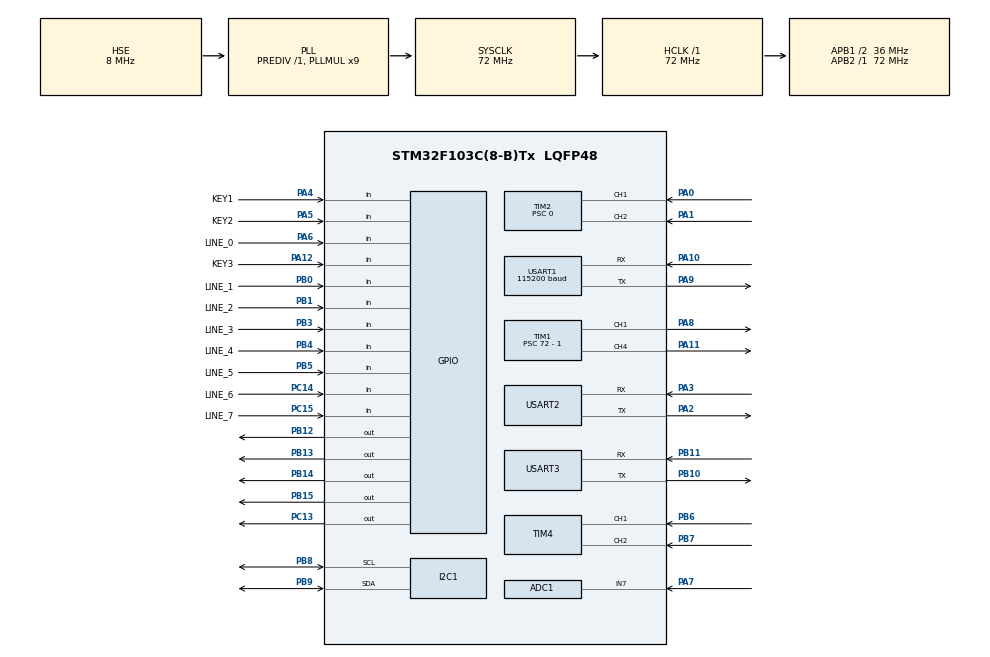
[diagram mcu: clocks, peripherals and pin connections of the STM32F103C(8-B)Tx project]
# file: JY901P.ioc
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ADC1.Channel-2\#ChannelRegularConversion=ADC_CHANNEL_7
ADC1.NbrOfConversionFlag=1
ADC1.Rank-2\#ChannelRegularConversion=1
ADC1.SamplingTime-2\#ChannelRegularConversion=ADC_SAMPLETIME_1CYCLE_5
ADC1.master=1
Dma.Request0=USART1_TX
Dma.Request1=USART1_RX
Dma.USART1_RX.1.Direction=DMA_PERIPH_TO_MEMORY
Dma.USART1_RX.1.Instance=DMA1_Channel5
Dma.USART1_RX.1.MemDataAlignment=DMA_MDATAALIGN_BYTE
Dma.USART1_RX.1.MemInc=DMA_MINC_ENABLE
Dma.USART1_RX.1.Mode=DMA_CIRCULAR
Dma.USART1_RX.1.PeriphDataAlignment=DMA_PDATAALIGN_BYTE
Dma.USART1_RX.1.PeriphInc=DMA_PINC_DISABLE
Dma.USART1_RX.1.Priority=DMA_PRIORITY_LOW
Dma.USART1_TX.0.Direction=DMA_MEMORY_TO_PERIPH
Dma.USART1_TX.0.Instance=DMA1_Channel4
Dma.USART1_TX.0.MemDataAlignment=DMA_MDATAALIGN_BYTE
Dma.USART1_TX.0.MemInc=DMA_MINC_ENABLE
Dma.USART1_TX.0.Mode=DMA_NORMAL
Dma.USART1_TX.0.PeriphDataAlignment=DMA_PDATAALIGN_BYTE
Dma.USART1_TX.0.PeriphInc=DMA_PINC_DISABLE
Dma.USART1_TX.0.Priority=DMA_PRIORITY_LOW
I2C1.I2C_Mode=I2C_Fast
Mcu.Family=STM32F1
Mcu.Name=STM32F103C(8-B)Tx
Mcu.Package=LQFP48
NVIC.DMA1_Channel4_IRQn=true\:0\:0\:false\:false\:true\:false\:true\:true
NVIC.DMA1_Channel5_IRQn=true\:0\:0\:false\:false\:true\:false\:true\:true
NVIC.PriorityGroup=NVIC_PRIORITYGROUP_4
NVIC.TIM2_IRQn=true\:0\:0\:false\:false\:true\:true\:true\:true
NVIC.TIM3_IRQn=true\:0\:0\:false\:false\:true\:true\:true\:true
NVIC.USART1_IRQn=true\:0\:0\:false\:false\:true\:true\:true\:true
NVIC.USART2_IRQn=true\:0\:0\:false\:false\:true\:true\:true\:true
NVIC.USART3_IRQn=true\:0\:0\:false\:false\:true\:true\:true\:true
PA0-WKUP.Signal=S_TIM2_CH1_ETR
PA1.Signal=S_TIM2_CH2
PA10.Mode=Asynchronous
PA10.Signal=USART1_RX
PA11.Signal=S_TIM1_CH4
PA12.GPIO_Label=KEY3
PA12.Signal=GPIO_Input
PA13.Mode=Serial_Wire
PA13.Signal=SYS_JTMS-SWDIO
PA14.Mode=Serial_Wire
PA14.Signal=SYS_JTCK-SWCLK
PA2.Mode=Asynchronous
PA2.Signal=USART2_TX
PA3.Mode=Asynchronous
PA3.Signal=USART2_RX
PA4.GPIO_Label=KEY1
PA4.Signal=GPIO_Input
PA5.GPIO_Label=KEY2
PA5.Signal=GPIO_Input
PA6.GPIO_Label=LINE_0
PA6.GPIO_PuPd=GPIO_PULLUP
PA6.Signal=GPIO_Input
PA7.Signal=ADCx_IN7
PA8.Signal=S_TIM1_CH1
PA9.Mode=Asynchronous
PA9.Signal=USART1_TX
PB0.GPIO_Label=LINE_1
PB0.GPIO_PuPd=GPIO_PULLUP
PB0.Signal=GPIO_Input
PB1.GPIO_Label=LINE_2
PB1.GPIO_PuPd=GPIO_PULLUP
PB1.Signal=GPIO_Input
PB10.Mode=Asynchronous
PB10.Signal=USART3_TX
PB11.Mode=Asynchronous
PB11.Signal=USART3_RX
PB12.Signal=GPIO_Output
PB13.Signal=GPIO_Output
PB14.Signal=GPIO_Output
PB15.Signal=GPIO_Output
PB3.GPIO_Label=LINE_3
PB3.GPIO_PuPd=GPIO_PULLUP
PB3.Signal=GPIO_Input
PB4.GPIO_Label=LINE_4
PB4.GPIO_PuPd=GPIO_PULLUP
PB4.Signal=GPIO_Input
PB5.GPIO_Label=LINE_5
PB5.GPIO_PuPd=GPIO_PULLUP
PB5.Signal=GPIO_Input
PB6.Signal=S_TIM4_CH1
PB7.Signal=S_TIM4_CH2
PB8.Mode=I2C
PB8.Signal=I2C1_SCL
PB9.Mode=I2C
PB9.Signal=I2C1_SDA
PC13-TAMPER-RTC.Signal=GPIO_Output
PC14-OSC32_IN.GPIO_Label=LINE_6
PC14-OSC32_IN.GPIO_PuPd=GPIO_PULLUP
PC14-OSC32_IN.Signal=GPIO_Input
PC15-OSC32_OUT.GPIO_Label=LINE_7
PC15-OSC32_OUT.GPIO_PuPd=GPIO_PULLUP
PC15-OSC32_OUT.Signal=GPIO_Input
PD0-OSC_IN.Mode=HSE-External-Oscillator
PD0-OSC_IN.Signal=RCC_OSC_IN
PD1-OSC_OUT.Mode=HSE-External-Oscillator
PD1-OSC_OUT.Signal=RCC_OSC_OUT
ProjectManager.HeapSize=0x200
ProjectManager.StackSize=0x400
ProjectManager.TargetToolchain=CMake
RCC.ADCPresc=RCC_ADCPCLK2_DIV6
RCC.AHBFreq_Value=72000000
RCC.APB1CLKDivider=RCC_HCLK_DIV2
RCC.APB1Freq_Value=36000000
RCC.APB1TimFreq_Value=72000000
RCC.APB2Freq_Value=72000000
RCC.APB2TimFreq_Value=72000000
RCC.HCLKFreq_Value=72000000
RCC.PLLMUL=RCC_PLL_MUL9
RCC.PLLSourceVirtual=RCC_PLLSOURCE_HSE
RCC.SYSCLKFreq_VALUE=72000000
RCC.SYSCLKSource=RCC_SYSCLKSOURCE_PLLCLK
RCC.USBFreq_Value=72000000
SH.ADCx_IN7.0=ADC1_IN7,IN7
SH.S_TIM1_CH1.0=TIM1_CH1,PWM Generation1 CH1
SH.S_TIM1_CH4.0=TIM1_CH4,PWM Generation4 CH4
SH.S_TIM2_CH1_ETR.0=TIM2_CH1,Encoder_Interface
SH.S_TIM2_CH2.0=TIM2_CH2,Encoder_Interface
SH.S_TIM4_CH1.0=TIM4_CH1,Encoder_Interface
SH.S_TIM4_CH2.0=TIM4_CH2,Encoder_Interface
TIM1.Channel-PWM\ Generation1\ CH1=TIM_CHANNEL_1
TIM1.Channel-PWM\ Generation4\ CH4=TIM_CHANNEL_4
TIM1.Period=999
TIM1.Prescaler=72 - 1
TIM2.EncoderMode=TIM_ENCODERMODE_TI12
TIM2.Period=65535
TIM2.Prescaler=0
TIM3.Period=1000 - 1
TIM3.Prescaler=72 -1 
TIM4.EncoderMode=TIM_ENCODERMODE_TI12
USART1.BaudRate=115200
USART1.VirtualMode=VM_ASYNC
USART2.VirtualMode=VM_ASYNC
USART3.VirtualMode=VM_ASYNC
VP_TIM1_VS_ClockSourceINT.Mode=Internal
VP_TIM3_VS_ClockSourceINT.Mode=Internal
board=custom

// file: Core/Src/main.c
/* USER CODE BEGIN Header */
/**
  ******************************************************************************
  * @file           : main.c
  * @brief          : Main program body
  ******************************************************************************
  * @attention
  *
  * Copyright (c) 2026 STMicroelectronics.
  * All rights reserved.
  *
  * This software is licensed under terms that can be found in the LICENSE file
  * in the root directory of this software component.
  * If no LICENSE file comes with this software, it is provided AS-IS.
  *
  ******************************************************************************
  */
/* USER CODE END Header */
#include "main.h"
#include "adc.h"
#include "dma.h"
#include "i2c.h"
#include "tim.h"
#include "usart.h"
#include "gpio.h"

/* USER CODE BEGIN Includes */
#include "task.h"
#include "uartdbg.h"
#include "motor_bujin.h"
/* USER CODE END Includes */

void SystemClock_Config(void);

int main(void)
{

  /* MCU Configuration--------------------------------------------------------*/

  /* Reset of all peripherals, Initializes the Flash interface and the Systick. */
  HAL_Init();

  /* Configure the system clock */
  SystemClock_Config();

  /* Initialize all configured peripherals */
  MX_GPIO_Init();
  MX_DMA_Init();
  MX_USART1_UART_Init();
  MX_TIM1_Init();
  MX_I2C1_Init();
  MX_TIM2_Init();
  MX_TIM3_Init();
  MX_TIM4_Init();
  MX_ADC1_Init();
  MX_USART2_UART_Init();
  MX_USART3_UART_Init();
  /* USER CODE BEGIN 2 */

  /* 任务调度：1ms 节拍 + DMA 发送 + 电机 FSM */
  task_init();
  // Motor_Step_EmergencyStop();  /* 上电后立即失能电机，避免意外碰撞 */
      /* ── 步进电机测试 ── */
      //  Motor_Step_MoveRel(REV2P(1), 1000);     // 转1圈
      // Motor_Step_MoveRel(DEG2P(90), 30); // 转90°

      /* USER CODE END 2 */

      /* Infinite loop */
      while (1) {

    /* USER CODE BEGIN 3 */
    task_poll();
  }
  /* USER CODE END 3 */
}

void SystemClock_Config(void)
{
  RCC_OscInitTypeDef RCC_OscInitStruct = {0};
  RCC_ClkInitTypeDef RCC_ClkInitStruct = {0};
  RCC_PeriphCLKInitTypeDef PeriphClkInit = {0};

  /** Initializes the RCC Oscillators according to the specified parameters
  * in the RCC_OscInitTypeDef structure.
  */
  RCC_OscInitStruct.OscillatorType = RCC_OSCILLATORTYPE_HSE;
  RCC_OscInitStruct.HSEState = RCC_HSE_ON;
  RCC_OscInitStruct.HSEPredivValue = RCC_HSE_PREDIV_DIV1;
  RCC_OscInitStruct.HSIState = RCC_HSI_ON;
  RCC_OscInitStruct.PLL.PLLState = RCC_PLL_ON;
  RCC_OscInitStruct.PLL.PLLSource = RCC_PLLSOURCE_HSE;
  RCC_OscInitStruct.PLL.PLLMUL = RCC_PLL_MUL9;
  if (HAL_RCC_OscConfig(&RCC_OscInitStruct) != HAL_OK)
  {
    Error_Handler();
  }

  /** Initializes the CPU, AHB and APB buses clocks
  */
  RCC_ClkInitStruct.ClockType = RCC_CLOCKTYPE_HCLK|RCC_CLOCKTYPE_SYSCLK
                              |RCC_CLOCKTYPE_PCLK1|RCC_CLOCKTYPE_PCLK2;
  RCC_ClkInitStruct.SYSCLKSource = RCC_SYSCLKSOURCE_PLLCLK;
  RCC_ClkInitStruct.AHBCLKDivider = RCC_SYSCLK_DIV1;
  RCC_ClkInitStruct.APB1CLKDivider = RCC_HCLK_DIV2;
  RCC_ClkInitStruct.APB2CLKDivider = RCC_HCLK_DIV1;

  if (HAL_RCC_ClockConfig(&RCC_ClkInitStruct, FLASH_LATENCY_2) != HAL_OK)
  {
    Error_Handler();
  }
  PeriphClkInit.PeriphClockSelection = RCC_PERIPHCLK_ADC;
  PeriphClkInit.AdcClockSelection = RCC_ADCPCLK2_DIV6;
  if (HAL_RCCEx_PeriphCLKConfig(&PeriphClkInit) != HAL_OK)
  {
    Error_Handler();
  }
}

/* USER CODE BEGIN 4 */
/*
 * TIM1 更新中断（仅高级定时器，需使用 TIM1_UP_IRQHandler）
 * 当前 TIM1 已用于电机 PWM，且 flash 仅剩 ~200B，
 * 若需在此添加计数逻辑，建议先精简其他模块腾出空间。
 *
 * 参考写法：
 *   void TIM1_UP_IRQHandler(void) {
 *     HAL_TIM_IRQHandler(&htim1);
 *     if (__HAL_TIM_GET_FLAG(&htim1, TIM_FLAG_UPDATE) != RESET) {
 *       if (__HAL_TIM_GET_IT_SOURCE(&htim1, TIM_IT_UPDATE) != RESET) {
 *         __HAL_TIM_CLEAR_IT(&htim1, TIM_IT_UPDATE);
 *         // 用户计数代码...
 *       }
 *     }
 *   }
 *
 * 目前用 TIM3 的 task_tick() 代替（见 task_poll 区域）。
 */
/* USER CODE END 4 */

void Error_Handler(void)
{
  __disable_irq();
  while (1)
  {
  }
}
